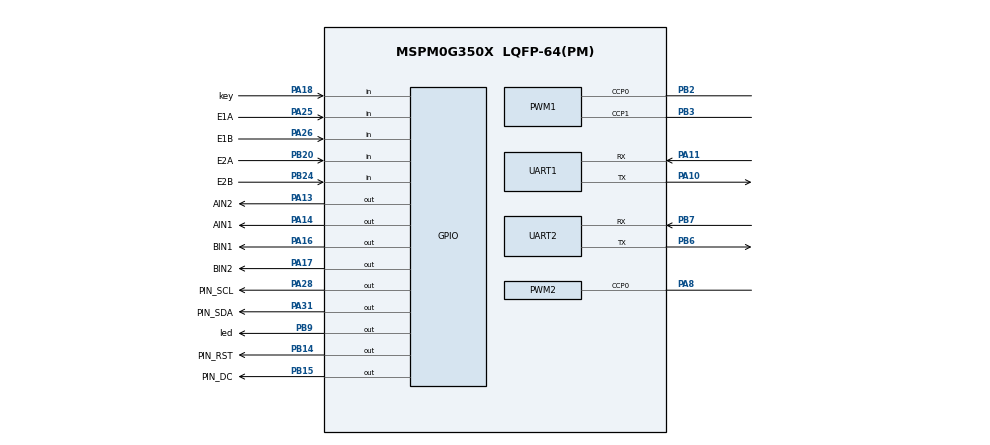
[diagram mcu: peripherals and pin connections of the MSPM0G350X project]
/**
 * @cliArgs --device "MSPM0G350X" --package "LQFP-64(PM)" --part "Default" --product "mspm0_sdk@2.01.00.03"
 * @versions {"tool":"1.20.0+3587"}
 */

/**
 * Import the modules used in this configuration.
 */
const ADC12   = scripting.addModule("/ti/driverlib/ADC12", {}, false);
const ADC121  = ADC12.addInstance();
const GPIO    = scripting.addModule("/ti/driverlib/GPIO", {}, false);
const GPIO1   = GPIO.addInstance();
const GPIO2   = GPIO.addInstance();
const GPIO3   = GPIO.addInstance();
const GPIO4   = GPIO.addInstance();
const GPIO5   = GPIO.addInstance();
const GPIO6   = GPIO.addInstance();
const GPIO7   = GPIO.addInstance();
const GPIO8   = GPIO.addInstance();
const GPIO9   = GPIO.addInstance();
const GPIO10  = GPIO.addInstance();
const GPIO11  = GPIO.addInstance();
const GPIO12  = GPIO.addInstance();
const PWM     = scripting.addModule("/ti/driverlib/PWM", {}, false);
const PWM1    = PWM.addInstance();
const PWM2    = PWM.addInstance();
const SYSCTL  = scripting.addModule("/ti/driverlib/SYSCTL");
const SYSTICK = scripting.addModule("/ti/driverlib/SYSTICK");
const TIMER   = scripting.addModule("/ti/driverlib/TIMER", {}, false);
const TIMER1  = TIMER.addInstance();
const UART    = scripting.addModule("/ti/driverlib/UART", {}, false);
const UART1   = UART.addInstance();
const UART2   = UART.addInstance();

/**
 * Write custom configuration values to the imported modules.
 */
const divider7       = system.clockTree["PLL_PDIV"];
divider7.divideValue = 2;

const divider9       = system.clockTree["UDIV"];
divider9.divideValue = 2;

const multiplier2         = system.clockTree["PLL_QDIV"];
multiplier2.multiplyValue = 5;

const mux8       = system.clockTree["HSCLKMUX"];
mux8.inputSelect = "HSCLKMUX_SYSPLL2X";

ADC121.$name                             = "ADC12_VOLTAGE";
ADC121.sampClkDiv                        = "DL_ADC12_CLOCK_DIVIDE_8";
ADC121.repeatMode                        = true;
ADC121.sampleTime0                       = "0.006 ms";
ADC121.enabledInterrupts                 = ["DL_ADC12_INTERRUPT_MEM0_RESULT_LOADED"];
ADC121.adcPin0Config.$name               = "ti_driverlib_gpio_GPIOPinGeneric0";
ADC121.adcPin0Config.hideOutputInversion = scripting.forceWrite(false);

const Board = scripting.addModule("/ti/driverlib/Board", {}, false);

GPIO1.$name                         = "OLED_RST";
GPIO1.associatedPins[0].$name       = "PIN_RST";
GPIO1.associatedPins[0].pin.$assign = "PB14";

GPIO2.$name                         = "OLED_DC";
GPIO2.associatedPins[0].$name       = "PIN_DC";
GPIO2.associatedPins[0].pin.$assign = "PB15";

GPIO3.$name                         = "OLED_SCL";
GPIO3.associatedPins[0].$name       = "PIN_SCL";
GPIO3.associatedPins[0].pin.$assign = "PA28";

GPIO4.$name                         = "OLED_SDA";
GPIO4.associatedPins[0].$name       = "PIN_SDA";
GPIO4.associatedPins[0].pin.$assign = "PA31";

GPIO5.$name                         = "KEY";
GPIO5.associatedPins[0].$name       = "key";
GPIO5.associatedPins[0].direction   = "INPUT";
GPIO5.associatedPins[0].pin.$assign = "PA18";

GPIO6.$name                         = "LED";
GPIO6.associatedPins[0].$name       = "led";
GPIO6.associatedPins[0].pin.$assign = "PB9";

GPIO7.port                          = "PORTA";
GPIO7.$name                         = "BIN";
GPIO7.associatedPins.create(2);
GPIO7.associatedPins[0].$name       = "BIN1";
GPIO7.associatedPins[0].pin.$assign = "PA16";
GPIO7.associatedPins[1].$name       = "BIN2";
GPIO7.associatedPins[1].pin.$assign = "PA17";

GPIO8.port                          = "PORTA";
GPIO8.$name                         = "AIN";
GPIO8.associatedPins.create(2);
GPIO8.associatedPins[0].$name       = "AIN1";
GPIO8.associatedPins[0].pin.$assign = "PA14";
GPIO8.associatedPins[1].$name       = "AIN2";
GPIO8.associatedPins[1].pin.$assign = "PA13";

GPIO9.$name                               = "ENCODERA";
GPIO9.associatedPins.create(2);
GPIO9.associatedPins[0].$name             = "E1A";
GPIO9.associatedPins[0].direction         = "INPUT";
GPIO9.associatedPins[0].polarity          = "RISE";
GPIO9.associatedPins[0].interruptPriority = "0";
GPIO9.associatedPins[0].interruptEn       = true;
GPIO9.associatedPins[0].pin.$assign       = "PA25";
GPIO9.associatedPins[1].$name             = "E1B";
GPIO9.associatedPins[1].direction         = "INPUT";
GPIO9.associatedPins[1].polarity          = "RISE";
GPIO9.associatedPins[1].interruptPriority = "0";
GPIO9.associatedPins[1].interruptEn       = true;
GPIO9.associatedPins[1].pin.$assign       = "PA26";

GPIO10.$name                               = "ENCODERB";
GPIO10.associatedPins.create(2);
GPIO10.associatedPins[0].$name             = "E2A";
GPIO10.associatedPins[0].direction         = "INPUT";
GPIO10.associatedPins[0].polarity          = "RISE";
GPIO10.associatedPins[0].interruptPriority = "0";
GPIO10.associatedPins[0].interruptEn       = true;
GPIO10.associatedPins[0].pin.$assign       = "PB20";
GPIO10.associatedPins[1].$name             = "E2B";
GPIO10.associatedPins[1].direction         = "INPUT";
GPIO10.associatedPins[1].polarity          = "RISE";
GPIO10.associatedPins[1].interruptPriority = "0";
GPIO10.associatedPins[1].interruptEn       = true;
GPIO10.associatedPins[1].pin.$assign       = "PB24";

GPIO11.$name                         = "GPIO_SI";
GPIO11.port                          = "PORTA";
GPIO11.associatedPins[0].$name       = "PIN_25";
GPIO11.associatedPins[0].assignedPin = "22";

GPIO12.$name                          = "GPIO_CLK";
GPIO12.associatedPins[0].$name        = "PIN_23";
GPIO12.associatedPins[0].assignedPin  = "9";
GPIO12.associatedPins[0].assignedPort = "PORTA";

PWM1.$name                      = "PWM_0";
PWM1.timerStartTimer            = true;
PWM1.pwmMode                    = "EDGE_ALIGN_UP";
PWM1.timerCount                 = 8000;
PWM1.peripheral.$assign         = "TIMA1";
PWM1.peripheral.ccp0Pin.$assign = "PB2";
PWM1.peripheral.ccp1Pin.$assign = "PB3";
PWM1.PWM_CHANNEL_0.$name        = "ti_driverlib_pwm_PWMTimerCC0";
PWM1.PWM_CHANNEL_1.$name        = "ti_driverlib_pwm_PWMTimerCC1";
PWM1.ccp0PinConfig.$name        = "ti_driverlib_gpio_GPIOPinGeneric4";
PWM1.ccp1PinConfig.$name        = "ti_driverlib_gpio_GPIOPinGeneric5";

PWM2.$name                      = "PWM_1";
PWM2.timerCount                 = 10000;
PWM2.clockDivider               = 8;
PWM2.clockPrescale              = 10;
PWM2.timerStartTimer            = true;
PWM2.ccIndex                    = [0];
PWM2.pwmMode                    = "EDGE_ALIGN_UP";
PWM2.peripheral.ccp0Pin.$assign = "PA8";
PWM2.PWM_CHANNEL_0.$name        = "ti_driverlib_pwm_PWMTimerCC2";
PWM2.PWM_CHANNEL_0.initVal      = "HIGH";
PWM2.PWM_CHANNEL_0.dutyCycle    = 15;
PWM2.ccp0PinConfig.$name        = "ti_driverlib_gpio_GPIOPinGeneric8";

SYSCTL.forceDefaultClkConfig = true;
SYSCTL.clockTreeEn           = true;

SYSTICK.periodEnable  = true;
SYSTICK.systickEnable = true;
SYSTICK.period        = 16777216;

TIMER1.$name              = "TIMER_0";
TIMER1.timerClkPrescale   = 32;
TIMER1.timerMode          = "PERIODIC";
TIMER1.timerPeriod        = "5 ms";
TIMER1.timerStartTimer    = true;
TIMER1.interrupts         = ["ZERO"];
TIMER1.peripheral.$assign = "TIMG0";

UART1.$name                    = "UART_0";
UART1.profile                  = "CONFIG_PROFILE_1";
UART1.peripheral.rxPin.$assign = "PA11";
UART1.peripheral.txPin.$assign = "PA10";
UART1.txPinConfig.$name        = "ti_driverlib_gpio_GPIOPinGeneric2";
UART1.rxPinConfig.$name        = "ti_driverlib_gpio_GPIOPinGeneric3";

UART2.$name                      = "UART_1";
UART2.enabledInterrupts          = ["DMA_DONE_RX"];
UART2.interruptPriority          = "1";
UART2.enabledDMARXTriggers       = "DL_UART_DMA_INTERRUPT_RX";
UART2.peripheral.$assign         = "UART1";
UART2.peripheral.rxPin.$assign   = "PB7";
UART2.peripheral.txPin.$assign   = "PB6";
UART2.txPinConfig.$name          = "ti_driverlib_gpio_GPIOPinGeneric6";
UART2.rxPinConfig.$name          = "ti_driverlib_gpio_GPIOPinGeneric7";
UART2.DMA_CHANNEL_RX.$name       = "DMA_CH0";
UART2.DMA_CHANNEL_RX.addressMode = "f2b";
UART2.DMA_CHANNEL_RX.srcLength   = "BYTE";
UART2.DMA_CHANNEL_RX.dstLength   = "BYTE";

/**
 * Pinmux solution for unlocked pins/peripherals. This ensures that minor changes to the automatic solver in a future
 * version of the tool will not impact the pinmux you originally saw.  These lines can be completely deleted in order to
 * re-solve from scratch.
 */
ADC121.peripheral.$suggestSolution               = "ADC1";
ADC121.peripheral.adcPin0.$suggestSolution       = "PA15";
Board.peripheral.$suggestSolution                = "DEBUGSS";
Board.peripheral.swclkPin.$suggestSolution       = "PA20";
Board.peripheral.swdioPin.$suggestSolution       = "PA19";
GPIO11.associatedPins[0].pin.$suggestSolution    = "PA22";
GPIO12.associatedPins[0].pin.$suggestSolution    = "PA9";
PWM2.peripheral.$suggestSolution                 = "TIMA0";
UART1.peripheral.$suggestSolution                = "UART0";
UART2.DMA_CHANNEL_RX.peripheral.$suggestSolution = "DMA_CH0";
